AUTOSAR XML (schema 00048)
package /AUTOLIV/SoftwareComponents/BMM
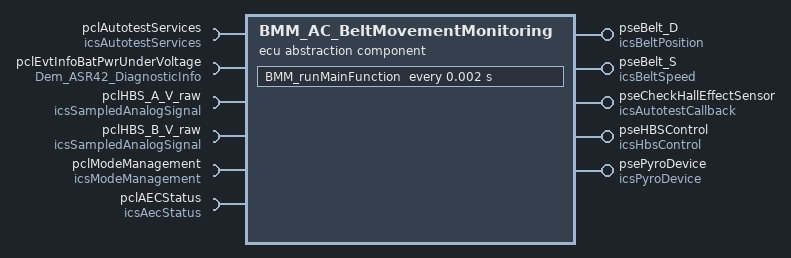
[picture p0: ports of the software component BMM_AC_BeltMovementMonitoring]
  ecu abstraction sw component type BMM_AC_BeltMovementMonitoring
    5 x require port:
      pclAutotestServices: required-com-specs=[GetLastCriticalAutotestID, GetTestResult], required-interface=icsAutotestServices
      pclEvtInfoBatPwrUnderVoltage: required-interface=Dem_ASR42_DiagnosticInfo
        required-com-specs:
          GetDTCOfEvent
          GetDebouncingOfEvent
          GetEventExtendedDataRecord
          GetEventExtendedDataRecordEx
          GetEventFailed
          GetEventFreezeFrameData
          GetEventFreezeFrameDataEx
          GetEventStatus
          GetEventTested
          GetFaultDetectionCounter
      pclHBS_A_V_raw: required-com-specs=[Get, Get_100ms, Get_10ms, Get_20ms, Get_2ms], required-interface=icsSampledAnalogSignal
      pclHBS_B_V_raw: required-com-specs=[Get, Get_100ms, Get_10ms, Get_20ms, Get_2ms], required-interface=icsSampledAnalogSignal
      pclModeManagement: client-com-spec=CheckModeStatus, required-interface=icsModeManagement
    5 x provide port:
      pseBelt_D: provided-interface=icsBeltPosition
        provided-com-specs:
          operation=GetFromMinPos_deg, queue-length=1
          operation=GetFromMinPos_mm, queue-length=1
          operation=GetFromT0_deg, queue-length=1
          operation=GetFromT0_mm, queue-length=1
          operation=GetRange_deg, queue-length=1
          operation=GetRange_mm, queue-length=1
      pseBelt_S: provided-interface=icsBeltSpeed
        provided-com-specs:
          operation=GetSpeed_SingleEdge_deg_s, queue-length=1
          operation=GetSpeed_deg_s, queue-length=1
          operation=GetSpeed_mm_s, queue-length=1
      pseCheckHallEffectSensor: server-com-spec{operation=AutotestCallback, queue-length=1}, provided-interface=icsAutotestCallback
      pseHBSControl: provided-com-specs=[{operation=DisableHBSMonitoring, queue-length=1}, {operation=EnableHBSMonitoring, queue-length=1}], provided-interface=icsHbsControl
      psePyroDevice: server-com-spec{operation=GetPyroActivationStatus, queue-length=1}, provided-interface=icsPyroDevice
    require port pclAECStatus: required-interface=icsAecStatus
      required-com-specs:
        SetAecEvent
        GetNumberOfImplementedAec
        GetAecStatus
        GetAecQualificationCount
        GetAecNvpBlockRecordingStatus
        GetAecGroupsStatus
        GetAecDeskillThrs
    behavior BMM_IB_BobbinRotatingSensor: data-type-mapping=DataTypeMappingSet_PP4G
      13 x operation invoked event:
        oie_pseCheckHallEffectSensor_AutotestCallback: start-on-event=BMM_Autotest_CheckHallEffectSensor, operation=pseCheckHallEffectSensor.AutotestCallback
        BMM_evDisableHBSMonitoring: start-on-event=BMM_runDisableHBSMonitoring, operation=pseHBSControl.DisableHBSMonitoring
        BMM_evEnableHBSMonitoring: start-on-event=BMM_runEnableHBSMonitoring, operation=pseHBSControl.EnableHBSMonitoring
        BMM_evGetPositionFromMinPos_deg: start-on-event=BMM_runGetPositionFromMinPos_deg, operation=pseBelt_D.GetFromMinPos_deg
        BMM_evGetPositionFromMinPos_mm: start-on-event=BMM_runGetPositionFromMinPos_mm, operation=pseBelt_D.GetFromMinPos_mm
        BMM_evGetPositionFromT0_deg: start-on-event=BMM_runGetPositionFromT0_deg, operation=pseBelt_D.GetFromT0_deg
        BMM_evGetPositionFromT0_mm: start-on-event=BMM_runGetPositionFromT0_mm, operation=pseBelt_D.GetFromT0_mm
        BMM_evGetPositionRange_deg: start-on-event=BMM_runGetPositionRange_deg, operation=pseBelt_D.GetRange_deg
        BMM_evGetPositionRange_mm: start-on-event=BMM_runGetPositionRange_mm, operation=pseBelt_D.GetRange_mm
        BMM_evGetPyroActivationStatus: start-on-event=BMM_runGetPyroActivationStatus, operation=psePyroDevice.GetPyroActivationStatus
        oie_pseBelt_S_GetSpeed_SingleEdge_deg_s: start-on-event=BMM_runGetSpeed_SingleEdge_deg_s, operation=pseBelt_S.GetSpeed_SingleEdge_deg_s
        BMM_evGetSpeed_deg_s: start-on-event=BMM_runGetSpeed_deg_s, operation=pseBelt_S.GetSpeed_deg_s
        BMM_evGetSpeed_mm_s: start-on-event=BMM_runGetSpeed_mm_s, operation=pseBelt_S.GetSpeed_mm_s
      timing event BMM_evMainFunction: start-on-event=BMM_runMainFunction, period=0.002
      init event BMM_runInitEvent: start-on-event=BMM_runInit
      15 x runnable:
        BMM_Autotest_CheckHallEffectSensor: can-be-invoked-concurrently=true
          7 x sync call:
            scp_GetEventStatus: operation=pclEvtInfoBatPwrUnderVoltage.GetEventStatus
            scp_GetTestResult: operation=pclAutotestServices.GetTestResult
            scp_Get_100ms: operation=pclHBS_A_V_raw.Get_100ms
            scp_Get_100ms1: operation=pclHBS_B_V_raw.Get_100ms
            SC_pclAECStatus_GetAecStatus: operation=pclAECStatus.GetAecStatus
            SC_pclHBS_A_V_raw_Get_10ms: operation=pclHBS_A_V_raw.Get_10ms
            SC_pclHBS_B_V_raw_Get_10ms: operation=pclHBS_B_V_raw.Get_10ms
        BMM_runDisableHBSMonitoring: can-be-invoked-concurrently=true
        BMM_runEnableHBSMonitoring: can-be-invoked-concurrently=true
        BMM_runGetPositionFromMinPos_deg: can-be-invoked-concurrently=true
        BMM_runGetPositionFromMinPos_mm: can-be-invoked-concurrently=true
        BMM_runGetPositionFromT0_deg: can-be-invoked-concurrently=true
        BMM_runGetPositionFromT0_mm: can-be-invoked-concurrently=true
        BMM_runGetPositionRange_deg: can-be-invoked-concurrently=true
        BMM_runGetPositionRange_mm: can-be-invoked-concurrently=true
        BMM_runGetPyroActivationStatus: can-be-invoked-concurrently=true
        BMM_runGetSpeed_SingleEdge_deg_s
        BMM_runGetSpeed_deg_s: can-be-invoked-concurrently=true
        BMM_runGetSpeed_mm_s: can-be-invoked-concurrently=true
        BMM_runInit: can-be-invoked-concurrently=true
        BMM_runMainFunction
          sync call scp_CheckModeStatus: operation=pclModeManagement.CheckModeStatus
  swc implementation BMM_impBobbinRotatingSensor: behavior=BMM_IB_BobbinRotatingSensor
    code-descriptors:
      code BMM_Impl_Code: artifact-descriptors=autosar-engineering-object=category=SWSRC
